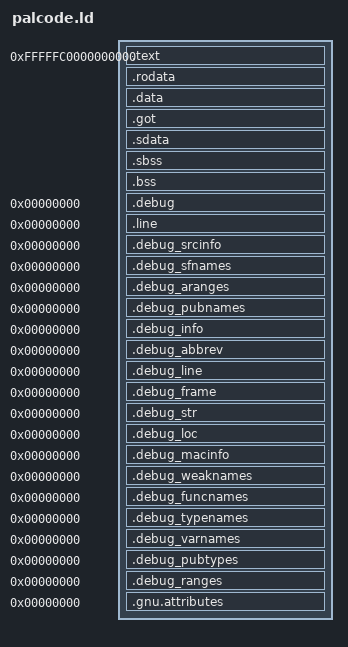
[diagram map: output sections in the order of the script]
OUTPUT_FORMAT("elf64-alpha")
ENTRY(__start)

SECTIONS
{
  . = 0xfffffc0000000000;
  .text : { *(.text*) }
  .rodata : { *(.rodata*) }
  .data ALIGN(8192) : { *(.data*) }
  .got : { *(.got.plt) *(.got) }
  .sdata : { *(.sdata*) }
  .sbss : { *(.sbss) *(.scommon) }
  .bss : {
    *(.bss.page_dir)
    *(.bss.stack)
    *(COMMON)
    *(.bss)
    PROVIDE (_end = .);
  }

  /* DWARF debug sections.
     Symbols in the DWARF debugging sections are relative to the beginning
     of the section so we begin them at 0.  */
  /* DWARF 1 */
  .debug          0 : { *(.debug) }
  .line           0 : { *(.line) }
  /* GNU DWARF 1 extensions */
  .debug_srcinfo  0 : { *(.debug_srcinfo) }
  .debug_sfnames  0 : { *(.debug_sfnames) }
  /* DWARF 1.1 and DWARF 2 */
  .debug_aranges  0 : { *(.debug_aranges) }
  .debug_pubnames 0 : { *(.debug_pubnames) }
  /* DWARF 2 */
  .debug_info     0 : { *(.debug_info .gnu.linkonce.wi.*) }
  .debug_abbrev   0 : { *(.debug_abbrev) }
  .debug_line     0 : { *(.debug_line) }
  .debug_frame    0 : { *(.debug_frame) }
  .debug_str      0 : { *(.debug_str) }
  .debug_loc      0 : { *(.debug_loc) }
  .debug_macinfo  0 : { *(.debug_macinfo) }
  /* SGI/MIPS DWARF 2 extensions */
  .debug_weaknames 0 : { *(.debug_weaknames) }
  .debug_funcnames 0 : { *(.debug_funcnames) }
  .debug_typenames 0 : { *(.debug_typenames) }
  .debug_varnames  0 : { *(.debug_varnames) }
  /* DWARF 3 */
  .debug_pubtypes 0 : { *(.debug_pubtypes) }
  .debug_ranges   0 : { *(.debug_ranges) }
  .gnu.attributes 0 : { KEEP (*(.gnu.attributes)) }

  /DISCARD/ : { *(.note.GNU-stack) *(.gnu_debuglink) *(.gnu.lto_*) }
  /DISCARD/ : { *(.eh_frame) }
}
